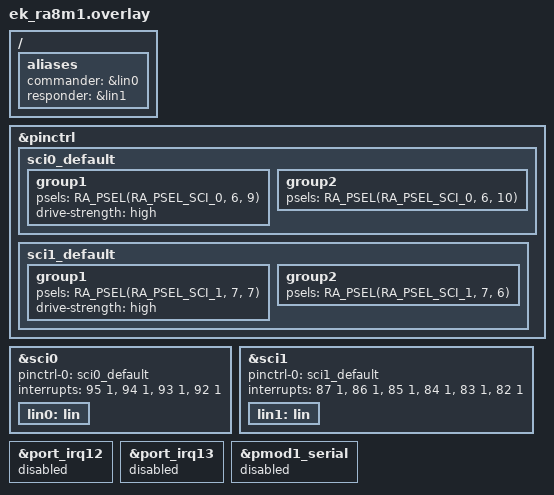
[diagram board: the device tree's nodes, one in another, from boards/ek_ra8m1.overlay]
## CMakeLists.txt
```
# SPDX-License-Identifier: Apache-2.0

cmake_minimum_required(VERSION 3.20.0)
find_package(Zephyr REQUIRED HINTS $ENV{ZEPHYR_BASE})
project(lin_api)

file(GLOB app_sources src/*.c)
target_sources(app PRIVATE ${app_sources})
```

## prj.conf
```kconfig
CONFIG_LIN=y
CONFIG_ZTEST=y
```

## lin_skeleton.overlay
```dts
/*
 * Copyright (c) 2025 Renesas Electronics Corporation
 *
 * SPDX-License-Identifier: Apache-2.0
 */

/ {
	aliases {
		commander = &lin_skeleton0;
		responder = &lin_skeleton1;
	};

	lin_skeleton0: lin_skeleton0 {
		compatible = "zephyr,lin-skeleton";
	};

	lin_skeleton1: lin_skeleton1 {
		compatible = "zephyr,lin-skeleton";
	};
};
```

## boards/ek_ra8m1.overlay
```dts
/*
 * Copyright (c) 2025 Renesas Electronics Corporation
 *
 * SPDX-License-Identifier: Apache-2.0
 */

/ {
	aliases {
		commander = &lin0;
		responder = &lin1;
	};
};

&pinctrl {
	sci0_default: sci0_default {
		group1 {
			/* TXD */
			psels = <RA_PSEL(RA_PSEL_SCI_0, 6, 9)>;
			drive-strength = "high";
		};

		group2 {
			/* RXD */
			psels = <RA_PSEL(RA_PSEL_SCI_0, 6, 10)>;
		};
	};

	sci1_default: sci1_default {
		group1 {
			/* TXD */
			psels = <RA_PSEL(RA_PSEL_SCI_1, 7, 7)>;
			drive-strength = "high";
		};

		group2 {
			/* RXD */
			psels = <RA_PSEL(RA_PSEL_SCI_1, 7, 6)>;
		};
	};
};

&sci0 {
	pinctrl-0 = <&sci0_default>;
	pinctrl-names = "default";
	interrupts = <95 1>, <94 1>, <93 1>, <92 1>;
	interrupt-names = "rxi", "txi", "tei", "eri";
	status = "okay";

	lin0: lin {
		status = "okay";
	};
};

&sci1 {
	pinctrl-0 = <&sci1_default>;
	pinctrl-names = "default";
	interrupts = <87 1>, <86 1>, <85 1>, <84 1>, <83 1>, <82 1>;
	interrupt-names = "rxi", "txi", "tei", "eri", "aed", "bfd";
	status = "okay";

	lin1: lin {
		status = "okay";
	};
};

/* Disable unused nodes that conflict with LIN interrupts */
&port_irq12 {
	status = "disabled";
};

&port_irq13 {
	status = "disabled";
};

&pmod1_serial {
	status = "disabled";
};
```

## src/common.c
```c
/*
 * Copyright (c) 2025 Renesas Electronics Corporation
 *
 * SPDX-License-Identifier: Apache-2.0
 */

#include <string.h>

#include <zephyr/drivers/lin.h>
#include <zephyr/kernel.h>
#include <zephyr/ztest.h>

#include "common.h"

ZTEST_DMEM const struct device *const lin_commander = DEVICE_DT_GET(LIN_COMMANDER);
ZTEST_DMEM const struct device *const lin_responder = DEVICE_DT_GET(LIN_RESPONDER);
ZTEST_DMEM const struct device *const commander_phy =
	DEVICE_DT_GET_OR_NULL(DT_PHANDLE(LIN_COMMANDER, phys));

ZTEST_DMEM const struct lin_config commander_cfg = {
	.mode = LIN_MODE_COMMANDER,
	.baudrate = LIN_BUS_BAUDRATE,
	.break_len = LIN_BUS_BREAK_LEN_COMMANDER,
	.break_delimiter_len = LIN_BUS_BREAK_DELIMITER_LEN,
	.flags = 0,
};

ZTEST_DMEM const struct lin_config responder_cfg = {
	.mode = LIN_MODE_RESPONDER,
	.baudrate = LIN_BUS_BAUDRATE,
	.break_len = LIN_BUS_BREAK_LEN_RESPONDER,
	.break_delimiter_len = LIN_BUS_BREAK_DELIMITER_LEN,
	.flags = IS_ENABLED(CONFIG_LIN_AUTO_SYNCHRONIZATION) ? LIN_BUS_AUTO_SYNC : 0,
};

ZTEST_DMEM const uint8_t lin_test_data[LIN_TEST_DATA_LEN] = {
	0x01, 0x02, 0x03, 0x04, 0x05, 0x06, 0x07, 0x08,
};

ZTEST_DMEM uint8_t rx_buffer[LIN_TEST_DATA_LEN];
ZTEST_DMEM struct k_sem transmission_completed;
ZTEST_DMEM struct lin_msg commander_msg;
ZTEST_DMEM struct lin_msg responder_msg;

void *test_lin_setup(void)
{
	k_sem_init(&transmission_completed, 0, 1);
	return NULL;
}

void test_lin_before(void *f)
{
	ARG_UNUSED(f);
	k_sem_reset(&transmission_completed);
	memset(&commander_msg, 0, sizeof(commander_msg));
	memset(&responder_msg, 0, sizeof(responder_msg));
}

void test_lin_after(void *f)
{
	ARG_UNUSED(f);
	lin_stop(lin_commander);
	lin_stop(lin_responder);
}
```

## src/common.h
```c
/*
 * Copyright (c) 2025 Renesas Electronics Corporation
 *
 * SPDX-License-Identifier: Apache-2.0
 */

#ifndef COMMON_H_
#define COMMON_H_

#include <zephyr/device.h>
#include <zephyr/drivers/lin.h>
#include <zephyr/kernel.h>

#if DT_NODE_HAS_STATUS_OKAY(DT_ALIAS(commander))
#define LIN_COMMANDER DT_ALIAS(commander)
#else
#error "Please set the correct LIN commander device"
#endif

#if DT_NODE_HAS_STATUS_OKAY(DT_ALIAS(responder))
#define LIN_RESPONDER DT_ALIAS(responder)
#else
#error "Please set the correct LIN responder device"
#endif

/**
 * @brief LIN bus configuration parameters
 */
#define LIN_BUS_BAUDRATE            19200U
#define LIN_BUS_BREAK_LEN_COMMANDER 13U
#define LIN_BUS_BREAK_LEN_RESPONDER 11U
#define LIN_BUS_BREAK_DELIMITER_LEN 1U

/**
 * @brief LIN IDs for testing
 */
#define LIN_COMMANDER_WRITE_ID 0x01
#define LIN_COMMANDER_READ_ID  0x02

/**
 * @brief Length of test data
 */
#define LIN_TEST_DATA_LEN LIN_MAX_DLEN

/**
 * @brief LIN devices to be used in tests
 */
extern const struct device *const lin_commander;
extern const struct device *const lin_responder;
extern const struct device *const commander_phy;

/**
 * @brief LIN configurations
 */
extern const struct lin_config commander_cfg;
extern const struct lin_config responder_cfg;

/**
 * @brief Test data
 */
extern const uint8_t lin_test_data[LIN_TEST_DATA_LEN];

/**
 * @brief Receive buffer
 */
extern uint8_t rx_buffer[LIN_TEST_DATA_LEN];

/**
 * @brief Semaphore to signal transmission completion
 */
extern struct k_sem transmission_completed;

/**
 * @brief LIN messages for commander and responder
 */
extern struct lin_msg commander_msg;
extern struct lin_msg responder_msg;

/**
 * @brief Test setup and teardown functions
 */
extern void *test_lin_setup(void);
extern void test_lin_before(void *f);
extern void test_lin_after(void *f);

#endif /* COMMON_H_ */
```

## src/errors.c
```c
/*
 * Copyright (c) 2025 Renesas Electronics Corporation
 *
 * SPDX-License-Identifier: Apache-2.0
 */

#include <string.h>

#include <zephyr/drivers/lin.h>
#include <zephyr/ztest.h>

#include "common.h"

/**
 * @addtogroup t_lin_driver
 * @{
 * @defgroup t_lin_errors test_lin_errors
 * @brief TestPurpose: verify LIN error handling functionality
 *
 * This test uses 2 nodes: a LIN commander node and a LIN responder node for testing parameter
 * handling in each mode.
 * @}
 */

ZTEST(lin_errors, test_lin_commander_errors)
{
	/** Dummy message for testing */
	struct lin_msg msg = {
		.id = LIN_COMMANDER_WRITE_ID,
		.data_len = LIN_TEST_DATA_LEN,
		.checksum_type = LIN_CHECKSUM_CLASSIC,
	};
	struct lin_filter filter;
	int ret;

	memcpy(msg.data, lin_test_data, LIN_TEST_DATA_LEN);

	ret = lin_configure(lin_commander, &commander_cfg);
	zassert_ok(ret, "Failed to configure LIN commander node");

	ret = lin_start(lin_commander);
	zassert_ok(ret, "Failed to start LIN commander node");

	ret = lin_start(lin_commander);
	zassert_equal(ret, -EALREADY,
		      "lin_start() should fail when starting an already started node");

	ret = lin_response(lin_commander, &msg, K_MSEC(100));
	zassert_equal(ret, -EPERM, "lin_response() should fail when called in commander mode");

	ret = lin_read(lin_commander, &msg, K_MSEC(100));
	zassert_equal(ret, -EPERM, "lin_read() should fail when called in commander mode");

	ret = lin_set_rx_filter(lin_commander, &filter);
	zassert_equal(ret, -EPERM, "lin_set_rx_filter() should fail when called in commander mode");

	ret = lin_stop(lin_commander);
	zassert_ok(ret, "Failed to stop LIN commander node");

	ret = lin_stop(lin_commander);
	zassert_equal(ret, -EALREADY,
		      "lin_stop() should fail when stopping an already stopped node");
}

ZTEST(lin_errors, test_lin_responder_errors)
{
	/** Dummy message for testing */
	struct lin_msg msg = {
		.id = LIN_COMMANDER_WRITE_ID,
		.data_len = LIN_TEST_DATA_LEN,
		.checksum_type = LIN_CHECKSUM_CLASSIC,
	};
	int ret;

	memcpy(msg.data, lin_test_data, LIN_TEST_DATA_LEN);

	ret = lin_configure(lin_responder, &responder_cfg);
	zassert_ok(ret, "Failed to configure LIN responder node");

	ret = lin_start(lin_responder);
	zassert_ok(ret, "Failed to start LIN responder node");

	ret = lin_start(lin_responder);
	zassert_equal(ret, -EALREADY,
		      "lin_start() should fail when starting an already started node");

	ret = lin_send(lin_responder, &msg, K_MSEC(100));
	zassert_equal(ret, -EPERM, "lin_send() should fail when called in responder mode");

	ret = lin_receive(lin_responder, &msg, K_MSEC(100));
	zassert_equal(ret, -EPERM, "lin_receive() should fail when called in responder mode");

	ret = lin_response(lin_responder, &msg, K_MSEC(100));
	zassert_equal(ret, -EFAULT, "lin_response() should fail when no header received");

	ret = lin_read(lin_responder, &msg, K_MSEC(100));
	zassert_equal(ret, -EFAULT, "lin_read() should fail when no header received");

	ret = lin_stop(lin_responder);
	zassert_ok(ret, "Failed to stop LIN responder node");

	ret = lin_stop(lin_responder);
	zassert_equal(ret, -EALREADY,
		      "lin_stop() should fail when stopping an already stopped node");
}

ZTEST_SUITE(lin_errors, NULL, test_lin_setup, test_lin_before, test_lin_after, NULL);
```

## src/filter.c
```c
/*
 * Copyright (c) 2025 Renesas Electronics Corporation
 *
 * SPDX-License-Identifier: Apache-2.0
 */

#include <zephyr/drivers/lin.h>
#include <zephyr/ztest.h>

#include "common.h"

/**
 * @addtogroup t_lin_driver
 * @{
 * @defgroup t_lin_filter test_lin_filter
 * @brief TestPurpose: verify LIN filter functionality
 *
 * This test uses 2 nodes: a LIN commander node and a LIN responder node for loopback testing.
 * @}
 */

static volatile uint32_t header_count;
static volatile uint8_t last_pid;

static void lin_filter_test_responder_callback(const struct device *dev,
					       const struct lin_event *event, void *user_data)
{
	ARG_UNUSED(dev);
	ARG_UNUSED(user_data);

	switch (event->type) {
	case LIN_EVT_RX_HEADER:
		header_count++;
		last_pid = event->header.pid;
		break;
	case LIN_EVT_TX_DATA:
		__fallthrough;
	case LIN_EVT_RX_DATA:
		__fallthrough;
	case LIN_EVT_RX_WAKEUP:
		__fallthrough;
	case LIN_EVT_ERR:
		__fallthrough;
	default:
		break;
	}
}

static void lin_filter_test_commander_callback(const struct device *dev,
					       const struct lin_event *event, void *user_data)
{
	ARG_UNUSED(dev);
	ARG_UNUSED(user_data);

	switch (event->type) {
	case LIN_EVT_TX_HEADER:
		k_sem_give(&transmission_completed);
		break;
	case LIN_EVT_TX_DATA:
		__fallthrough;
	case LIN_EVT_RX_DATA:
		__fallthrough;
	case LIN_EVT_RX_HEADER:
		__fallthrough;
	case LIN_EVT_TX_WAKEUP:
		__fallthrough;
	case LIN_EVT_RX_WAKEUP:
		__fallthrough;
	default:
		break;
	}
}

static int test_lin_filter_test_startup(void)
{
	int ret;

	/* Set commander event handler */
	ret = lin_set_event_callback(lin_commander, lin_filter_test_commander_callback, NULL);
	if (ret != 0) {
		return ret;
	}

	/* Set responder event handler */
	ret = lin_set_event_callback(lin_responder, lin_filter_test_responder_callback, NULL);
	if (ret != 0) {
		return ret;
	}

	/* Configure LIN commander and responder nodes */
	ret = lin_configure(lin_commander, &commander_cfg);
	if (ret != 0) {
		return ret;
	}

	ret = lin_configure(lin_responder, &responder_cfg);
	if (ret != 0) {
		return ret;
	}

	/* Start LIN communication */
	ret = lin_start(lin_responder);
	if (ret != 0) {
		return ret;
	}

	ret = lin_start(lin_commander);
	if (ret != 0) {
		return ret;
	}

	return ret;
}

static int test_lin_filter_set(uint8_t frame_id, uint8_t mask)
{
	struct lin_filter filter;

	filter.primary_pid = frame_id;
	filter.secondary_pid = 0;
	filter.mask = mask;

	return lin_set_rx_filter(lin_responder, &filter);
}

static int test_lin_header_send(uint8_t frame_id)
{
	struct lin_msg msg;

	msg.id = frame_id;
	msg.data_len = 0;
	msg.checksum_type = LIN_CHECKSUM_CLASSIC;

	return lin_send(lin_commander, &msg, K_FOREVER);
}

ZTEST(lin_filter, test_accept_ids)
{
	uint8_t test_pids[] = {0xA6, 0xA3, 0xA8, 0xAD};
	int ret;

	header_count = 0;
	last_pid = 0;

	ret = test_lin_filter_test_startup();
	zassert_ok(ret, "Failed to start LIN filter test");

	/* Set filter to accept IDs 0xA0 - 0xAF */
	ret = test_lin_filter_set(0xA0, 0xF0);
	zassert_ok(ret, "Failed to set LIN filter");

	/* Send IDs that match the filter */
	for (size_t i = 0; i < ARRAY_SIZE(test_pids); i++) {
		ret = test_lin_header_send(lin_get_frame_id(test_pids[i]));
		zassert_ok(ret, "Failed to send LIN header with ID 0x%02X: ret=%d", test_pids[i],
			   ret);

		ret = k_sem_take(&transmission_completed, K_MSEC(1000));
		zassert_ok(ret, "Last transmission is not completed: Frame ID 0x%02X",
			   test_pids[i]);

		/* Verify that only IDs matching the filter were received */
		zassert_equal(header_count, (i + 1),
			      "Unexpected number of headers received: %d != %d", header_count,
			      (i + 1));
		zassert_equal(last_pid, test_pids[i],
			      "Last PID received (0x%02X) does not match filter", last_pid);
	}
}

ZTEST(lin_filter, test_reject_ids)
{
	uint8_t test_pids[] = {0x80, 0xC1, 0x42, 0x03};
	int ret;

	header_count = 0;
	last_pid = 0;

	ret = test_lin_filter_test_startup();
	zassert_ok(ret, "Failed to start LIN filter test");

	/* Set filter to accept ID 0x20 */
	ret = test_lin_filter_set(0x20, 0xFF);
	zassert_ok(ret, "Failed to set LIN filter");

	/* Send IDs that do not match the filter */
	for (size_t i = 0; i < ARRAY_SIZE(test_pids); i++) {
		ret = test_lin_header_send(lin_get_frame_id(test_pids[i]));
		zassert_ok(ret, "Failed to send LIN header with ID 0x%02X", test_pids[i]);

		ret = k_sem_take(&transmission_completed, K_MSEC(1000));
		zassert_ok(ret, "Last transmission is not completed: Frame ID 0x%02X",
			   test_pids[i]);

		/* Verify that no IDs matching the filter were received */
		zassert_equal(header_count, 0, "Unexpected headers received");
		zassert_equal(last_pid, 0, "Last PID received (0x%02X) should be zero", last_pid);
	}
}

ZTEST_SUITE(lin_filter, NULL, test_lin_setup, test_lin_before, test_lin_after, NULL);
```

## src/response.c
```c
/*
 * Copyright (c) 2025 Renesas Electronics Corporation
 *
 * SPDX-License-Identifier: Apache-2.0
 */

#include <string.h>

#include <zephyr/drivers/lin.h>
#include <zephyr/ztest.h>

#include "common.h"

/**
 * @addtogroup t_lin_driver
 * @{
 * @defgroup t_lin_basic_api test_lin_basic_api
 * @brief Test Purpose: Verify the basic functionality of the LIN API by using a commander node to
 * write and read a frame to and from a responder node, then verify data integrity.
 *
 * This test uses 2 nodes: a LIN commander node and a LIN responder node for loopback testing.
 * @}
 */

static void responder_evt_callback(const struct device *dev, const struct lin_event *event,
				   void *user_data)
{
	struct lin_msg *responder_msg = user_data;
	int ret;

	ARG_UNUSED(dev);

	switch (event->type) {
	case LIN_EVT_RX_HEADER: {
		uint8_t id = lin_get_frame_id(event->header.pid);

		if (!lin_verify_pid(event->header.pid)) {
			TC_PRINT("LIN received invalid ID\n");
			return;
		}

		if (id == LIN_COMMANDER_WRITE_ID) {
			ret = lin_read(lin_responder, responder_msg, K_FOREVER);
			if (ret) {
				TC_PRINT("LIN responder read failed\n");
				return;
			}
		} else if (id == LIN_COMMANDER_READ_ID) {
			ret = lin_response(lin_responder, responder_msg, K_FOREVER);
			if (ret) {
				TC_PRINT("LIN responder send failed\n");
				return;
			}
		} else {
			TC_PRINT("Unexpected LIN ID\n");
			return;
		}

		break;
	}
	case LIN_EVT_TX_DATA: {
		if (event->status != 0) {
			TC_PRINT("LIN responder data transfer error: %d\n", event->status);
			return;
		}

		break;
	}
	case LIN_EVT_RX_DATA: {
		if (event->status != 0) {
			TC_PRINT("LIN responder data transfer error: %d\n", event->status);
			return;
		}

		if (lin_get_frame_id(event->data.pid) == LIN_COMMANDER_WRITE_ID) {
			k_sem_give(&transmission_completed);
		}

		break;
	}
	case LIN_EVT_RX_WAKEUP:
		__fallthrough;
	case LIN_EVT_ERR:
		__fallthrough;
	default:
		break;
	}
}

static void commander_evt_callback(const struct device *dev, const struct lin_event *event,
				   void *user_data)
{
	switch (event->type) {
	case LIN_EVT_TX_HEADER: {
		if (event->status != 0) {
			TC_PRINT("LIN commander header write error: %d\n", event->status);
			return;
		}

		break;
	}
	case LIN_EVT_TX_DATA: {
		if (event->status != 0) {
			TC_PRINT("LIN commander data write error: %d\n", event->status);
			return;
		}

		break;
	}
	case LIN_EVT_RX_DATA: {
		if (event->status != 0) {
			TC_PRINT("LIN commander data transfer error: %d\n", event->status);
			return;
		}

		if (lin_get_frame_id(event->data.pid) == LIN_COMMANDER_READ_ID) {
			k_sem_give(&transmission_completed);
		}

		break;
	}
	case LIN_EVT_RX_HEADER:
		__fallthrough;
	case LIN_EVT_RX_WAKEUP:
		__fallthrough;
	case LIN_EVT_ERR:
		__fallthrough;
	default:
		break;
	}
}

void test_lin_prepare_data(struct lin_msg *tx_msg, struct lin_msg *rx_msg, uint8_t frame_id)
{
	tx_msg->id = frame_id;
	tx_msg->data_len = LIN_TEST_DATA_LEN;
	tx_msg->checksum_type = LIN_CHECKSUM_CLASSIC;
	memcpy(tx_msg->data, lin_test_data, LIN_TEST_DATA_LEN);

	rx_msg->id = frame_id;
	rx_msg->data_len = LIN_TEST_DATA_LEN;
	rx_msg->checksum_type = LIN_CHECKSUM_CLASSIC;
}

static int test_lin_basic_api(bool is_read)
{
	int ret;

	/* 1. Configure LIN commander and responder nodes */
	ret = lin_configure(lin_commander, &commander_cfg);
	if (ret) {
		TC_PRINT("LIN configure failed\n");
		return TC_FAIL;
	}

	ret = lin_configure(lin_responder, &responder_cfg);
	if (ret) {
		TC_PRINT("LIN responder configure failed\n");
		return TC_FAIL;
	}

	/* 2. Allow LIN communication */
	ret = lin_start(lin_responder);
	if (ret) {
		TC_PRINT("LIN responder start failed\n");
		return TC_FAIL;
	}

	ret = lin_start(lin_commander);
	if (ret) {
		TC_PRINT("LIN start failed\n");
		return TC_FAIL;
	}

	if (!is_read) {
		/* 3. Commander send header + data frames (if any) to responder */
		ret = lin_send(lin_commander, &commander_msg, K_FOREVER);
		if (ret) {
			TC_PRINT("LIN send failed\n");
			return TC_FAIL;
		}
	} else {
		/* 3. Commander send header frame to responder to read data */
		ret = lin_receive(lin_commander, &commander_msg, K_FOREVER);
		if (ret) {
			TC_PRINT("LIN commander read failed\n");
			return TC_FAIL;
		}
	}

	/* 4. Wait for transmission completed */
	ret = k_sem_take(&transmission_completed, K_MSEC(1000));
	if (ret) {
		TC_PRINT("Transmission timeout\n");
		return TC_FAIL;
	}

	return TC_PASS;
}

ZTEST(lin_basic_api, test_lin_configure)
{
	struct lin_config config_tmp;
	int ret;

	zassert_true(device_is_ready(lin_commander), "LIN commander device is not ready");
	zassert_true(device_is_ready(lin_responder), "LIN responder device is not ready");

	/* Configure LIN commander */
	ret = lin_configure(lin_commander, &commander_cfg);
	zassert_ok(ret, "Failed to configure LIN commander");

	/* Verify LIN commander configuration */
	ret = lin_get_config(lin_commander, &config_tmp);
	zassert_ok(ret, "Failed to get LIN commander config");
	zassert_mem_equal(&config_tmp, &commander_cfg, sizeof(commander_cfg),
			  "LIN commander config mismatch");

	/* Configure LIN responder */
	ret = lin_configure(lin_responder, &responder_cfg);
	zassert_ok(ret, "Failed to configure LIN responder");

	/* Verify LIN responder configuration */
	ret = lin_get_config(lin_responder, &config_tmp);
	zassert_ok(ret, "Failed to get LIN responder config");
	zassert_mem_equal(&config_tmp, &responder_cfg, sizeof(responder_cfg),
			  "LIN responder config mismatch");
}

ZTEST(lin_basic_api, test_commander_write)
{
	int ret;

	test_lin_prepare_data(&commander_msg, &responder_msg, LIN_COMMANDER_WRITE_ID);

	/* Set commander event handler */
	ret = lin_set_event_callback(lin_commander, commander_evt_callback, &commander_msg);
	zassert_ok(ret, "Failed to set commander event callback");

	/* Set responder event handler */
	ret = lin_set_event_callback(lin_responder, responder_evt_callback, &responder_msg);
	zassert_ok(ret, "Failed to set responder event callback");

	/* Run the LIN commander write test */
	ret = test_lin_basic_api(false);
	zassert_ok(ret, "LIN commander write test failed");

	/* Verify LIN received data */
	zassert_equal(commander_msg.id, responder_msg.id,
		      "LIN received ID [%x] does not match sent ID [%x]", responder_msg.id,
		      commander_msg.id);
	zassert_mem_equal(responder_msg.data, lin_test_data, LIN_TEST_DATA_LEN,
			  "LIN received data does not match sent data");
}

ZTEST(lin_basic_api, test_commander_read)
{
	int ret;

	test_lin_prepare_data(&responder_msg, &commander_msg, LIN_COMMANDER_READ_ID);

	/* Set commander event handler */
	ret = lin_set_event_callback(lin_commander, commander_evt_callback, &commander_msg);
	zassert_ok(ret, "Failed to set commander event callback");

	/* Set responder event handler */
	ret = lin_set_event_callback(lin_responder, responder_evt_callback, &responder_msg);
	zassert_ok(ret, "Failed to set responder event callback");

	/* Run the commander read test */
	ret = test_lin_basic_api(true);
	zassert_ok(ret, "LIN commander read test failed");

	/* Verify LIN received data */
	zassert_equal(commander_msg.id, responder_msg.id,
		      "LIN received ID [%x] does not match sent ID [%x]", responder_msg.id,
		      commander_msg.id);
	zassert_mem_equal(commander_msg.data, lin_test_data, LIN_TEST_DATA_LEN,
			  "LIN received data does not match sent data");
}

ZTEST_SUITE(lin_basic_api, NULL, test_lin_setup, test_lin_before, test_lin_after, NULL);
```

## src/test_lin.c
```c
/*
 * Copyright (c) 2025 Renesas Electronics Corporation
 *
 * SPDX-License-Identifier: Apache-2.0
 */

/**
 * @addtogroup t_lin_api
 * @{
 * @defgroup t_lin_api_basic test_lin_api_basic
 * @brief TestPurpose: verify LIN API basic functionality
 *
 * This test uses 2 nodes: a LIN master node and a LIN slave node for loopback testing.
 * @}
 */

#include <zephyr/drivers/lin.h>
#include <zephyr/kernel.h>
#include <zephyr/ztest.h>

#if DT_NODE_HAS_STATUS_OKAY(DT_ALIAS(master))
#define LIN_MASTER DT_ALIAS(master)
#else
#error "Please set the correct LIN master device"
#endif

#if DT_NODE_HAS_STATUS_OKAY(DT_ALIAS(slave))
#define LIN_SLAVE DT_ALIAS(slave)
#else
#error "Please set the correct LIN slave device"
#endif

#define LIN_BUS_BAUDRATE            19200U
#define LIN_BUS_BREAK_LEN           13U
#define LIN_BUS_BREAK_DELIMITER_LEN 2U

#define LIN_MASTER_WRITE_ID 0x01
#define LIN_MASTER_READ_ID  0x02

static const struct device *const lin_master = DEVICE_DT_GET(LIN_MASTER);
static const struct device *const lin_slave = DEVICE_DT_GET(LIN_SLAVE);

static const struct lin_config master_cfg = {
	.mode = LIN_MODE_COMMANDER,
	.baudrate = LIN_BUS_BAUDRATE,
	.break_len = LIN_BUS_BREAK_LEN,
	.break_delimiter_len = LIN_BUS_BREAK_DELIMITER_LEN,
	.flags = 0,
};

static const struct lin_config slave_cfg = {
	.mode = LIN_MODE_RESPONDER,
	.baudrate = LIN_BUS_BAUDRATE,
	.break_len = LIN_BUS_BREAK_LEN,
	.break_delimiter_len = LIN_BUS_BREAK_DELIMITER_LEN,
	.flags = 0,
};

static const uint8_t data[LIN_MAX_DLEN] = {0x01, 0x02, 0x03, 0x04, 0x05, 0x06, 0x07, 0x08};
static struct k_sem transmission_completed;
static struct lin_msg slave_msg;

static void slave_evt_callback(const struct device *dev, const struct lin_event *event,
			       void *user_data)
{
	ARG_UNUSED(dev);
	ARG_UNUSED(user_data);
	int ret;

	switch (event->type) {
	case LIN_EVT_RX_HEADER:
		if (event->pid == LIN_MASTER_WRITE_ID) {
			ret = lin_read(lin_slave, &slave_msg, K_FOREVER);
			if (ret) {
				TC_PRINT("LIN slave read failed\n");
				return;
			}
		} else if (event->pid == LIN_MASTER_READ_ID) {
			ret = lin_response(lin_slave, &slave_msg, K_FOREVER);
			if (ret) {
				TC_PRINT("LIN slave send failed\n");
				return;
			}
		} else {
			TC_PRINT("Unexpected LIN ID\n");
			return;
		}
		break;
	case LIN_EVT_TX_DATA:
	case LIN_EVT_RX_DATA:
	case LIN_EVT_RX_WAKEUP:
	case LIN_EVT_ERR:
	default:
		break;
	}
}

static void master_evt_callback(const struct device *dev, const struct lin_event *event,
				void *user_data)
{
	ARG_UNUSED(dev);
	ARG_UNUSED(user_data);

	switch (event->type) {
	case LIN_EVT_TX_DATA:
	case LIN_EVT_RX_DATA:
		k_sem_give(&transmission_completed);
		break;
	case LIN_EVT_RX_HEADER:
	case LIN_EVT_RX_WAKEUP:
	case LIN_EVT_ERR:
	default:
		break;
	}
}

static int test_lin_basic_api(struct lin_msg *master_msg, struct lin_msg *slave_msg)
{
	int ret;

	/* 1. Configure LIN master and slave nodes */
	ret = lin_configure(lin_master, &master_cfg);
	if (ret) {
		TC_PRINT("LIN configure failed\n");
		return TC_FAIL;
	}

	ret = lin_configure(lin_slave, &slave_cfg);
	if (ret) {
		TC_PRINT("LIN slave configure failed\n");
		return TC_FAIL;
	}

	/* 2. Allow LIN communication */
	ret = lin_start(lin_master);
	if (ret) {
		TC_PRINT("LIN start failed\n");
		return TC_FAIL;
	}

	ret = lin_start(lin_slave);
	if (ret) {
		TC_PRINT("LIN slave start failed\n");
		return TC_FAIL;
	}

	/* 3. Master send header + data frames to slave */
	ret = lin_send(lin_master, master_msg, K_FOREVER);
	if (ret) {
		TC_PRINT("LIN send failed\n");
		return TC_FAIL;
	}

	/* 4. Wait for transmission completed */
	ret = k_sem_take(&transmission_completed, K_MSEC(100));
	if (ret) {
		TC_PRINT("Master write timeout\n");
		return TC_FAIL;
	}

	return TC_PASS;
}

static void *test_lin_setup(void)
{
	k_sem_init(&transmission_completed, 0, 1);

	return NULL;
}

static void test_lin_before(void *f)
{
	ARG_UNUSED(f);

	k_sem_reset(&transmission_completed);
}

static void test_lin_after(void *f)
{
	ARG_UNUSED(f);

	lin_stop(lin_master);
	lin_stop(lin_slave);
}

static void test_lin_teardown(void *f)
{
	ARG_UNUSED(f);
}

ZTEST(lin_api_basic, test_lin_configure)
{
	struct lin_config config_tmp;
	int ret;

	zassert_true(device_is_ready(lin_master), "LIN master device is not ready");
	zassert_true(device_is_ready(lin_slave), "LIN slave device is not ready");

	/* Configure LIN master */
	ret = lin_configure(lin_master, &master_cfg);
	zassert_ok(ret, "Failed to configure LIN master");

	/* Verify LIN master configuration */
	ret = lin_get_config(lin_master, &config_tmp);
	zassert_ok(ret, "Failed to get LIN master config");
	zassert_mem_equal(&config_tmp, &master_cfg, sizeof(master_cfg),
			  "LIN master config mismatch");

	/* Configure LIN slave */
	ret = lin_configure(lin_slave, &slave_cfg);
	zassert_ok(ret, "Failed to configure LIN slave");

	/* Verify LIN slave configuration */
	ret = lin_get_config(lin_slave, &config_tmp);
	zassert_ok(ret, "Failed to get LIN slave config");
	zassert_mem_equal(&config_tmp, &slave_cfg, sizeof(slave_cfg), "LIN slave config mismatch");
}

ZTEST(lin_api_basic, test_lin_master_write)
{
	struct lin_msg lin_master_msg = {
		.id = LIN_MASTER_WRITE_ID,
		.data_len = LIN_MAX_DLEN,
		.checksum_type = LIN_CHECKSUM_CLASSIC,
	};
	int ret;

	/* Prepare master message write data */
	memcpy(lin_master_msg.data, data, LIN_MAX_DLEN);

	zassert_true(device_is_ready(lin_master), "LIN master device is not ready");
	zassert_true(device_is_ready(lin_slave), "LIN slave device is not ready");

	/* Set master event handler */
	ret = lin_set_callback(lin_master, master_evt_callback, NULL);
	zassert_ok(ret, "Failed to set master event callback");

	/* Set slave event handler */
	ret = lin_set_callback(lin_slave, slave_evt_callback, NULL);
	zassert_ok(ret, "Failed to set slave event callback");

	/* Run the LIN master write test */
	ret = test_lin_basic_api(&lin_master_msg, &slave_msg);
	zassert_ok(ret, "LIN master write test failed");

	/* Verify LIN received data */
	zassert_equal(slave_msg.id, lin_master_msg.id, "LIN received ID does not match sent ID");
	zassert_mem_equal(slave_msg.data, lin_master_msg.data, lin_master_msg.data_len,
			  "LIN received data does not match sent data");
}

ZTEST(lin_api_basic, test_lin_master_read)
{
	struct lin_msg lin_master_msg = {
		.id = LIN_MASTER_READ_ID,
		.data_len = LIN_MAX_DLEN,
		.checksum_type = LIN_CHECKSUM_CLASSIC,
	};
	int ret;

	/* Prepare slave message response data */
	memcpy(slave_msg.data, data, LIN_MAX_DLEN);

	zassert_true(device_is_ready(lin_master), "LIN master device is not ready");
	zassert_true(device_is_ready(lin_slave), "LIN slave device is not ready");

	/* Set master event handler */
	ret = lin_set_callback(lin_master, master_evt_callback, NULL);
	zassert_ok(ret, "Failed to set master event callback");

	/* Set slave event handler */
	ret = lin_set_callback(lin_slave, slave_evt_callback, NULL);
	zassert_ok(ret, "Failed to set slave event callback");

	/* Run the master read test */
	ret = test_lin_basic_api(&lin_master_msg, &slave_msg);
	zassert_ok(ret, "LIN master read test failed");

	/* Verify LIN received data */
	zassert_equal(lin_master_msg.id, slave_msg.id, "LIN received ID does not match sent ID");
	zassert_mem_equal(lin_master_msg.data, slave_msg.data, lin_master_msg.data_len,
			  "LIN received data does not match sent data");
}

ZTEST_SUITE(lin_api_basic, NULL, test_lin_setup, test_lin_before, test_lin_after,
	    test_lin_teardown);
```

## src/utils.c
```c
/*
 * Copyright (c) 2025 Renesas Electronics Corporation
 *
 * SPDX-License-Identifier: Apache-2.0
 */

#include <zephyr/drivers/lin.h>
#include <zephyr/ztest.h>

#include "common.h"

/**
 * @addtogroup t_lin_driver
 * @{
 * @defgroup t_lin_utils test_lin_utils
 * @brief TestPurpose: verify LIN utility functions
 * @}
 */

ZTEST(lin_api_utils, test_lin_pid_calculate)
{
	/*
	 * Valid LIN IDs and their corresponding PIDs
	 *
	 * Reference: Table of Valid Frame Identifiers (Section 2.8.2) - LIN Specification Package
	 * Rev 2.2A
	 */

	const uint8_t valid_id[] = {
		0x00, 0x01, 0x02, 0x03, 0x04, 0x05, 0x06, 0x07, 0x08, 0x09, 0x0A, 0x0B, 0x0C,
		0x0D, 0x0E, 0x0F, 0x10, 0x11, 0x12, 0x13, 0x14, 0x15, 0x16, 0x17, 0x18, 0x19,
		0x1A, 0x1B, 0x1C, 0x1D, 0x1E, 0x1F, 0x20, 0x21, 0x22, 0x23, 0x24, 0x25, 0x26,
		0x27, 0x28, 0x29, 0x2A, 0x2B, 0x2C, 0x2D, 0x2E, 0x2F, 0x30, 0x31, 0x32, 0x33,
		0x34, 0x35, 0x36, 0x37, 0x38, 0x39, 0x3A, 0x3B, 0x3C, 0x3D, 0x3E, 0x3F,
	};

	const uint8_t valid_pid[] = {
		0x80, 0xC1, 0x42, 0x03, 0xC4, 0x85, 0x06, 0x47, 0x08, 0x49, 0xCA, 0x8B, 0x4C,
		0x0D, 0x8E, 0xCF, 0x50, 0x11, 0x92, 0xD3, 0x14, 0x55, 0xD6, 0x97, 0xD8, 0x99,
		0x1A, 0x5B, 0x9C, 0xDD, 0x5E, 0x1F, 0x20, 0x61, 0xE2, 0xA3, 0x64, 0x25, 0xA6,
		0xE7, 0xA8, 0xE9, 0x6A, 0x2B, 0xEC, 0xAD, 0x2E, 0x6F, 0xF0, 0xB1, 0x32, 0x73,
		0xB4, 0xF5, 0x76, 0x37, 0x78, 0x39, 0xBA, 0xFB, 0x3C, 0x7D, 0xFE, 0xBF,
	};

	for (size_t i = 0; i < ARRAY_SIZE(valid_id); i++) {
		uint8_t computed_pid = lin_compute_pid(valid_id[i]);

		zassert_equal(computed_pid, valid_pid[i],
			      "lin_compute_pid failed for ID 0x%02X: expected 0x%02X, got 0x%02X",
			      valid_id[i], valid_pid[i], computed_pid);
	}

	for (size_t i = 0; i < ARRAY_SIZE(valid_pid); i++) {
		uint8_t computed_id = lin_get_frame_id(valid_pid[i]);

		zassert_equal(computed_id, valid_id[i],
			      "lin_get_frame_id failed for PID 0x%02X: expected 0x%02X, got 0x%02X",
			      valid_pid[i], valid_id[i], computed_id);
	}

	for (size_t i = 0; i < ARRAY_SIZE(valid_pid); i++) {
		bool is_valid = lin_verify_pid(valid_pid[i]);

		zassert_true(is_valid,
			     "lin_verify_pid failed for valid PID 0x%02X: expected true, got false",
			     valid_pid[i]);
	}
}

ZTEST(lin_api_utils, test_lin_transceiver)
{
	const struct device *phy = lin_get_transceiver(lin_commander);

	zassert_equal(phy, commander_phy, "wrong LIN transceiver device pointer returned");
}

ZTEST_SUITE(lin_api_utils, NULL, NULL, NULL, NULL, NULL);
```
